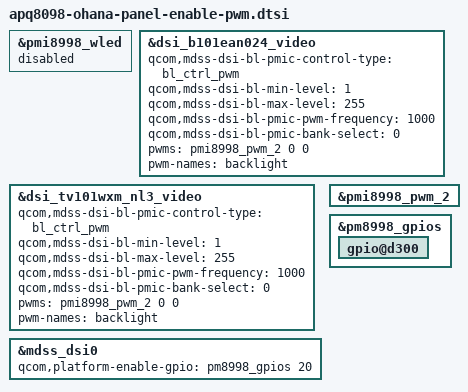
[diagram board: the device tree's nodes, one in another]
/* Copyright (c) 2016, The Linux Foundation. All rights reserved.
 *
 * This program is free software; you can redistribute it and/or modify
 * it under the terms of the GNU General Public License version 2 and
 * only version 2 as published by the Free Software Foundation.
 *
 * This program is distributed in the hope that it will be useful,
 * but WITHOUT ANY WARRANTY; without even the implied warranty of
 * MERCHANTABILITY or FITNESS FOR A PARTICULAR PURPOSE.  See the
 * GNU General Public License for more details.
 */


&pmi8998_wled {
	status = "disabled";
};

&dsi_b101ean024_video {
	qcom,mdss-dsi-bl-pmic-control-type = "bl_ctrl_pwm";
	qcom,mdss-dsi-bl-min-level = <1>;
	qcom,mdss-dsi-bl-max-level = <255>;
	qcom,mdss-dsi-bl-pmic-pwm-frequency = <1000>;
	qcom,mdss-dsi-bl-pmic-bank-select = <0>;
	pwms = <&pmi8998_pwm_2 0 0>; /* BACKLIGHT_PWM */
	pwm-names = "backlight";
};

&dsi_tv101wxm_nl3_video {
	qcom,mdss-dsi-bl-pmic-control-type = "bl_ctrl_pwm";
	qcom,mdss-dsi-bl-min-level = <1>;
	qcom,mdss-dsi-bl-max-level = <255>;
	qcom,mdss-dsi-bl-pmic-pwm-frequency = <1000>;
	qcom,mdss-dsi-bl-pmic-bank-select = <0>;
	pwms = <&pmi8998_pwm_2 0 0>; /* BACKLIGHT_PWM */
	pwm-names = "backlight";
};

&mdss_dsi0 {
	qcom,platform-enable-gpio = <&pm8998_gpios 20 0>; /* BACKLIGHT_PWR_EN */
};

/* Enable PMI-LPG2 (GPIO5) for backlight PWM */
&pmi8998_pwm_2 {
	status = "ok";
};

&pm8998_gpios {
	gpio@d300 { /* GPIO 20 - BACKLIGHT_PWR_EN */
		status = "ok";
	};
};

